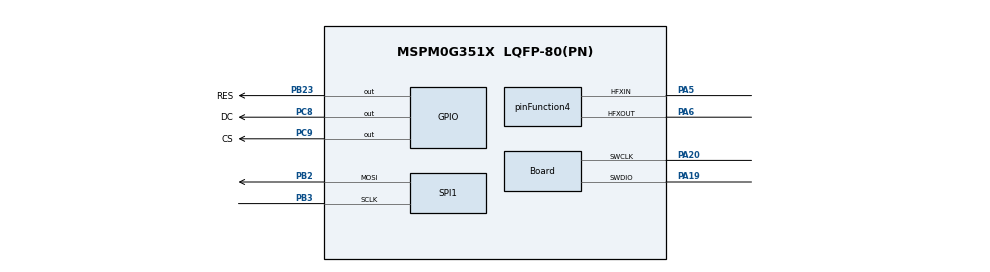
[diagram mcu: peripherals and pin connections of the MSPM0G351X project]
/**
 * @cliArgs --device "MSPM0G351X" --part "Default" --package "LQFP-80(PN)" --product "mspm0_sdk@2.08.00.03"
 * @versions {"tool":"1.25.0+4268"}
 */

/**
 * Import the modules used in this configuration.
 */
const GPIO   = scripting.addModule("/ti/driverlib/GPIO", {}, false);
const GPIO1  = GPIO.addInstance();
const SPI    = scripting.addModule("/ti/driverlib/SPI", {}, false);
const SPI1   = SPI.addInstance();
const SYSCTL = scripting.addModule("/ti/driverlib/SYSCTL");
const TRNG   = scripting.addModule("/ti/driverlib/TRNG");

/**
 * Write custom configuration values to the imported modules.
 */
const divider2       = system.clockTree["HFCLK4MFPCLKDIV"];
divider2.divideValue = 10;

const divider9       = system.clockTree["UDIV"];
divider9.divideValue = 2;

const gate7  = system.clockTree["MFCLKGATE"];
gate7.enable = true;

const gate8  = system.clockTree["MFPCLKGATE"];
gate8.enable = true;

const multiplier2         = system.clockTree["PLL_QDIV"];
multiplier2.multiplyValue = 4;

const mux4       = system.clockTree["EXHFMUX"];
mux4.inputSelect = "EXHFMUX_XTAL";

const mux8       = system.clockTree["HSCLKMUX"];
mux8.inputSelect = "HSCLKMUX_SYSPLL0";

const mux10       = system.clockTree["MFPCLKMUX"];
mux10.inputSelect = "MFPCLKMUX_HFCLK";

const mux12       = system.clockTree["SYSPLLMUX"];
mux12.inputSelect = "zSYSPLLMUX_HFCLK";

const pinFunction4                        = system.clockTree["HFXT"];
pinFunction4.inputFreq                    = 40;
pinFunction4.enable                       = true;
pinFunction4.HFXTStartup                  = 10;
pinFunction4.peripheral.$assign           = "SYSCTL";
pinFunction4.peripheral.hfxInPin.$assign  = "PA5";
pinFunction4.peripheral.hfxOutPin.$assign = "PA6";

const pinFunction6     = system.clockTree["LFXT"];
pinFunction6.inputFreq = 32.768;

GPIO1.$name                         = "OLED";
GPIO1.associatedPins.create(3);
GPIO1.associatedPins[0].$name       = "RES";
GPIO1.associatedPins[0].pin.$assign = "PB23";
GPIO1.associatedPins[1].$name       = "DC";
GPIO1.associatedPins[1].pin.$assign = "PC8";
GPIO1.associatedPins[2].$name       = "CS";
GPIO1.associatedPins[2].pin.$assign = "PC9";

const Board                       = scripting.addModule("/ti/driverlib/Board", {}, false);
Board.peripheral.$assign          = "DEBUGSS";
Board.peripheral.swclkPin.$assign = "PA20";
Board.peripheral.swdioPin.$assign = "PA19";

SPI1.$name                      = "SPI_0";
SPI1.targetBitRate              = 20000000;
SPI1.frameFormat                = "MOTO3";
SPI1.polarity                   = "1";
SPI1.direction                  = "PICO";
SPI1.sclkPinConfig.$name        = "ti_driverlib_gpio_GPIOPinGeneric0";
SPI1.mosiPinConfig.$name        = "ti_driverlib_gpio_GPIOPinGeneric1";
SPI1.peripheral.$assign         = "SPI0";
SPI1.peripheral.sclkPin.$assign = "PB3";
SPI1.peripheral.mosiPin.$assign = "PB2";

SYSCTL.forceDefaultClkConfig = true;
SYSCTL.clockTreeEn           = true;

TRNG.clockDivider = "DL_TRNG_CLOCK_DIVIDE_8";

const ProjectConfig              = scripting.addModule("/ti/project_config/ProjectConfig", {}, false);
ProjectConfig.migrationCondition = true;
